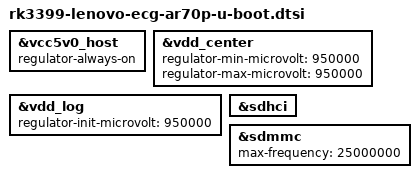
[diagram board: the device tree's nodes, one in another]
// SPDX-License-Identifier: GPL-2.0+

#include "rk3399-u-boot.dtsi"

&vcc5v0_host {
	regulator-always-on;
};

&vdd_center {
	regulator-min-microvolt = <950000>;
	regulator-max-microvolt = <950000>;
};

&vdd_log {
	regulator-init-microvolt = <950000>;
};

/*
 * Cap eMMC to 8-bit High Speed (52 MHz) in U-Boot: Samsung AJTD4R eMMC fails
 * block reads under U-Boot's Arasan SDHCI HS400ES mode. Linux still uses HS400ES.
 */
&sdhci {
	/delete-property/ mmc-hs400-1_8v;
	/delete-property/ mmc-hs400-enhanced-strobe;
	/delete-property/ mmc-hs200-1_8v;
};

/*
 * Cap SD card speed in SPL/U-Boot to avoid data CRC errors during boot.
 */
&sdmmc {
	/delete-property/ clock-freq-min-max;
	max-frequency = <25000000>;
};
